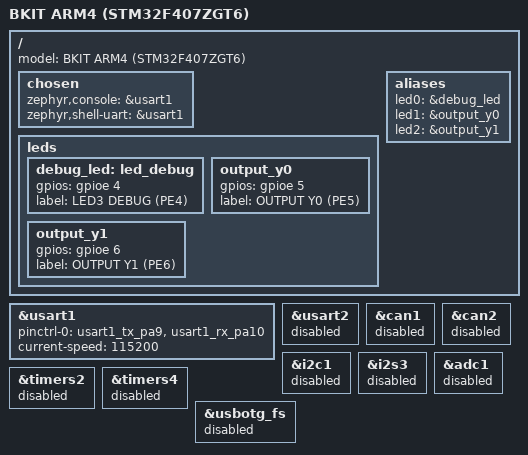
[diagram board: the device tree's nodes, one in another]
/*
 * app.overlay - Devicetree overlay cho Kit BKIT ARM4 (STM32F407ZGT6)
 *
 * Board gốc: stm32f4_disco (cùng chip STM32F407, thạch anh HSE 8 MHz,
 * SYSCLK 168 MHz). File này "vá" lại board gốc cho đúng phần cứng BKIT.
 */

/ {
	model = "BKIT ARM4 (STM32F407ZGT6)";

	/* 1. Chọn USART1 (PA9/PA10 -> MAX232 -> cổng RS232 DB9) làm console */
	chosen {
		zephyr,console = &usart1;
		zephyr,shell-uart = &usart1;
	};

	/* 2. Khai báo LED3 (LED DEBUG) nối vào chân PE4, tích cực mức cao */
	leds {
		debug_led: led_debug {
			gpios = <&gpioe 4 GPIO_ACTIVE_HIGH>;
			label = "LED3 DEBUG (PE4)";
		};

		/* Output Y0 / Y1 (qua opto ra cổng 12V) - có LED trạng thái trên kit */
		output_y0: output_y0 {
			gpios = <&gpioe 5 GPIO_ACTIVE_HIGH>;
			label = "OUTPUT Y0 (PE5)";
		};

		output_y1: output_y1 {
			gpios = <&gpioe 6 GPIO_ACTIVE_HIGH>;
			label = "OUTPUT Y1 (PE6)";
		};
	};

	/* 3. Trỏ các bí danh về phần cứng BKIT (chương trình dùng led0/led1/led2) */
	aliases {
		led0 = &debug_led;	/* LED3   - PE4 */
		led1 = &output_y0;	/* Out Y0 - PE5 */
		led2 = &output_y1;	/* Out Y1 - PE6 */
		/delete-property/ led3;	/* LED xanh dương của Discovery: không dùng */
	};
};

/* USART1: PA9 = TX, PA10 = RX (xem Bảng 7 - ARM_KIT.pdf) */
&usart1 {
	pinctrl-0 = <&usart1_tx_pa9 &usart1_rx_pa10>;
	pinctrl-names = "default";
	current-speed = <115200>;
	status = "okay";
};

/*
 * 4. Tắt các ngoại vi của board Discovery có chân trùng với phần cứng BKIT
 *    (PA2/PA3 nối ESP8266, PD0/PD1 nối FSMC, PB6/PB9 nối I2C/CAN, ...)
 */
&usart2 { status = "disabled"; };
&can1 { status = "disabled"; };
&can2 { status = "disabled"; };
&i2c1 { status = "disabled"; };
&i2s3 { status = "disabled"; };
&adc1 { status = "disabled"; };
&timers2 { status = "disabled"; };
&timers4 { status = "disabled"; };
&usbotg_fs { status = "disabled"; };
